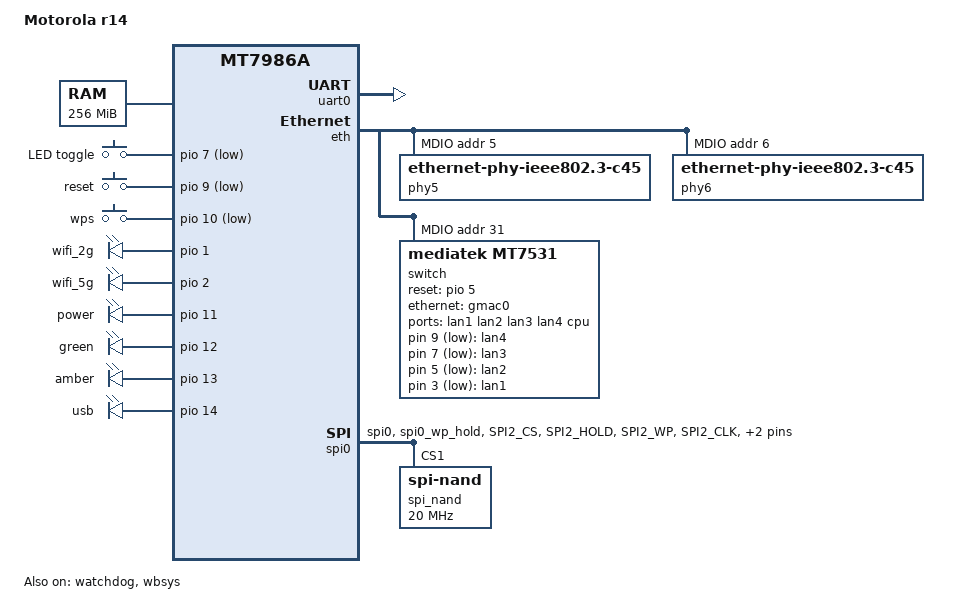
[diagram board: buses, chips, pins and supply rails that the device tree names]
/dts-v1/;
#include "mt7986a.dtsi"
#include "mt7986a-pinctrl.dtsi"
#include <dt-bindings/gpio/gpio.h>
#include <dt-bindings/input/linux-event-codes.h>
/ {
	model = "Motorola r14";
	compatible = "motorola,r14";

	chosen {
		bootargs = "console=ttyS0,115200n1 loglevel=8  \
				earlycon=uart8250,mmio32,0x11002000";
	};

	memory {
		reg = <0 0x40000000 0 0x10000000>;
	};

	gpio-keys {
		compatible = "gpio-keys";

		led_toggle {
			label = "LED toggle";
			linux,code = <KEY_LIGHTS_TOGGLE>;
			gpios = <&pio 7 GPIO_ACTIVE_LOW>;			
		};

		reset {
			label = "reset";
			linux,code = <KEY_RESTART>;
			gpios = <&pio 9 GPIO_ACTIVE_LOW>;			
		};

		wps {
			label = "wps";
			linux,code = <KEY_WPS_BUTTON>;
			gpios = <&pio 10 GPIO_ACTIVE_LOW>;
		};
	};

	leds {
		compatible = "gpio-leds";

		wifi_2g {
			label = "wifi_2g";
			gpios = <&pio 1 GPIO_ACTIVE_HIGH>;
			default-state = "off";
		};

		wifi_5g {
			label = "wifi_5g";
			gpios = <&pio 2 GPIO_ACTIVE_HIGH>;
			default-state = "off";
		};

		power {
			label = "power";
			gpios = <&pio 11 GPIO_ACTIVE_HIGH>;
			default-state = "on";
		};

		green {
			label = "green";
			gpios = <&pio 12 GPIO_ACTIVE_HIGH>;
			default-state = "off";
		};

		amber {
			label = "amber";
			gpios = <&pio 13 GPIO_ACTIVE_HIGH>;
			default-state = "off";
		};

		usb {
			label = "usb";
			gpios = <&pio 14 GPIO_ACTIVE_HIGH>;
			default-state = "off";
		};

		lan4 {
			label = "lan4";
			gpios = <&switch 9 GPIO_ACTIVE_LOW>;
			default-state = "off";
		};

		lan3 {
			label = "lan3";
			gpios = <&switch 7 GPIO_ACTIVE_LOW>;
			default-state = "off";
		};

		lan2 {
			label = "lan2";
			gpios = <&switch 5 GPIO_ACTIVE_LOW>;
			default-state = "off";
		};

		lan1 {
			label = "lan1";
			gpios = <&switch 3 GPIO_ACTIVE_LOW>;
			default-state = "off";
		};
        };


	nmbm_spim_nand {
		compatible = "generic,nmbm";

		#address-cells = <1>;
		#size-cells = <1>;

		lower-mtd-device = <&spi_nand>;
		forced-create;

		partitions {
			compatible = "fixed-partitions";
			#address-cells = <1>;
			#size-cells = <1>;

			partition@0 {
				label = "BL2";
				reg = <0x00000 0x0100000>;
				read-only;
			};

			partition@100000 {
				label = "u-boot-env";
				reg = <0x0100000 0x0060000>;
			};

			partition@160000 {
				label = "certificates";
				reg = <0x0160000 0x0020000>;
			};

			factory: partition@180000 {
				label = "Factory";
				reg = <0x180000 0x0200000>;
			};

			partition@380000 {
				label = "FIP";
				reg = <0x380000 0x0200000>;
			};

			partition@580000 {
				label = "ubi";
				reg = <0x580000 0x4000000>;
			};
		};
	};
};

&uart0 {
	status = "okay";
};

&watchdog {
	status = "okay";
};

&eth {
	status = "okay";

	gmac0: mac@0 {
		compatible = "mediatek,eth-mac";
		reg = <0>;
		phy-mode = "2500base-x";

		fixed-link {
			speed = <2500>;
			full-duplex;
			pause;
		};
	};

	gmac1: mac@1 {
		compatible = "mediatek,eth-mac";
		reg = <1>;
		phy-mode = "2500base-x";
		phy-handle = <&phy6>;
	};

	mdio: mdio-bus {
		#address-cells = <1>;
		#size-cells = <0>;

		reset-gpios = <&pio 6 1>;
		reset-delay-us = <600>;

		phy5: phy@5 {
			compatible = "ethernet-phy-ieee802.3-c45";
			reg = <5>;
		};

		phy6: phy@6 {
			compatible = "ethernet-phy-ieee802.3-c45";
			reg = <6>;
		};

		switch: switch@0 {
			compatible = "mediatek,mt7531";
			gpio-controller;
			#gpio-cells = <2>;
			reg = <31>;
			reset-gpios = <&pio 5 0>;

			ports {
				#address-cells = <1>;
				#size-cells = <0>;

				port@1 {
					reg = <1>;
					label = "lan1";
				};

				port@2 {
					reg = <2>;
					label = "lan2";
				};

				port@3 {
					reg = <3>;
					label = "lan3";
				};

				port@4 {
					reg = <4>;
					label = "lan4";
				};

				port@6 {
					reg = <6>;
					label = "cpu";
					ethernet = <&gmac0>;
					phy-mode = "2500base-x";

					fixed-link {
						speed = <2500>;
						full-duplex;
						pause;
					};
				};
			};
		};
	};
};

&spi0 {
	pinctrl-names = "default";
	pinctrl-0 = <&spi_flash_pins>;
	cs-gpios = <0>, <0>;
	status = "okay";

	spi_nand: spi_nand@1 {
		#address-cells = <1>;
		#size-cells = <1>;
		compatible = "spi-nand";
		reg = <1>;
		spi-max-frequency = <20000000>;
		spi-tx-buswidth = <4>;
		spi-rx-buswidth = <4>;
	};
};

&wbsys {
	mediatek,mtd-eeprom = <&factory 0x0000>;
	status = "okay";
	pinctrl-names = "default", "dbdc";
	pinctrl-0 = <&wf_2g_5g_pins>;
	pinctrl-1 = <&wf_dbdc_pins>;
};

&pio {
	spi_flash_pins: spi-flash-pins-33-to-38 {
		mux {
			function = "flash";
			groups = "spi0", "spi0_wp_hold";
		};
		conf-pu {
			pins = "SPI2_CS", "SPI2_HOLD", "SPI2_WP";
			drive-strength = <MTK_DRIVE_8mA>;
			bias-pull-up = <MTK_PUPD_SET_R1R0_11>;
		};
		conf-pd {
			pins = "SPI2_CLK", "SPI2_MOSI", "SPI2_MISO";
			drive-strength = <MTK_DRIVE_8mA>;
			bias-pull-down = <MTK_PUPD_SET_R1R0_11>;
		};
	};

	wf_2g_5g_pins: wf_2g_5g-pins {
		mux {
			function = "wifi";
			groups = "wf_2g", "wf_5g";
		};
		conf {
			pins = "WF0_HB1", "WF0_HB2", "WF0_HB3", "WF0_HB4",
			       "WF0_HB0", "WF0_HB0_B", "WF0_HB5", "WF0_HB6",
			       "WF0_HB7", "WF0_HB8", "WF0_HB9", "WF0_HB10",
			       "WF0_TOP_CLK", "WF0_TOP_DATA", "WF1_HB1",
			       "WF1_HB2", "WF1_HB3", "WF1_HB4", "WF1_HB0",
			       "WF1_HB5", "WF1_HB6", "WF1_HB7", "WF1_HB8",
			       "WF1_TOP_CLK", "WF1_TOP_DATA";
			drive-strength = <MTK_DRIVE_4mA>;
		};
	};

	wf_dbdc_pins: wf_dbdc-pins {
		mux {
			function = "wifi";
			groups = "wf_dbdc";
		};
		conf {
			pins = "WF0_HB1", "WF0_HB2", "WF0_HB3", "WF0_HB4",
			       "WF0_HB0", "WF0_HB0_B", "WF0_HB5", "WF0_HB6",
			       "WF0_HB7", "WF0_HB8", "WF0_HB9", "WF0_HB10",
			       "WF0_TOP_CLK", "WF0_TOP_DATA", "WF1_HB1",
			       "WF1_HB2", "WF1_HB3", "WF1_HB4", "WF1_HB0",
			       "WF1_HB5", "WF1_HB6", "WF1_HB7", "WF1_HB8",
			       "WF1_TOP_CLK", "WF1_TOP_DATA";
			drive-strength = <MTK_DRIVE_4mA>;
		};
	};
};

